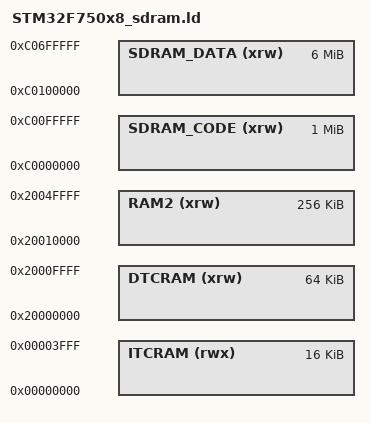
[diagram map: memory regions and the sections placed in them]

MEMORY
{
  ITCRAM (rwx)      :  ORIGIN = 0x00000000, LENGTH = 16K
  DTCRAM (xrw)      :  ORIGIN = 0x20000000, LENGTH = 64K
  RAM2(xrw)         :  ORIGIN = 0x20010000, LENGTH = 256K

  SDRAM_CODE(xrw)   :  ORIGIN = 0xC0000000, LENGTH = 1024K
  SDRAM_DATA(xrw)   :  ORIGIN = 0xC0100000, LENGTH = 6144K
}

REGION_ALIAS("TEXT", SDRAM_CODE);
REGION_ALIAS("RAM", DTCRAM);

INCLUDE armm_default_noflash.ld

